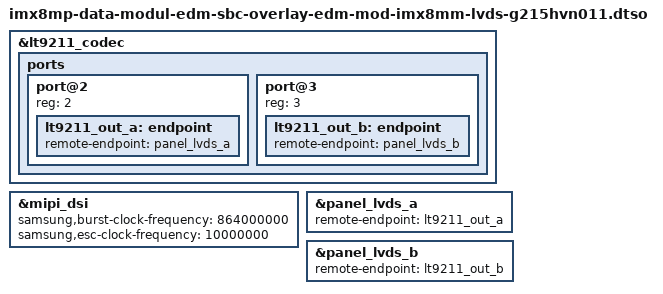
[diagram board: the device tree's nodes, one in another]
// SPDX-License-Identifier: (GPL-2.0+ OR MIT)
/*
 * Copyright 2022-2026 Marek Vasut
 */

#include "imx8mp-data-modul-edm-sbc-overlay-edm-mod-imx8mm-lvds.dtsi"
#include "imx8mp-data-modul-edm-sbc-overlay-lvds-g215hvn011.dtsi"

&lt9211_codec {
	ports {
		port@2 {
			reg = <2>;

			lt9211_out_a: endpoint {
				remote-endpoint = <&panel_lvds_a>;
			};
		};

		port@3 {
			reg = <3>;

			lt9211_out_b: endpoint {
				remote-endpoint = <&panel_lvds_b>;
			};
		};
	};
};

&mipi_dsi {
	samsung,burst-clock-frequency = <864000000>;
	samsung,esc-clock-frequency = <10000000>;
};

&panel_lvds_a {
	remote-endpoint = <&lt9211_out_a>;
};

&panel_lvds_b {
	remote-endpoint = <&lt9211_out_b>;
};
